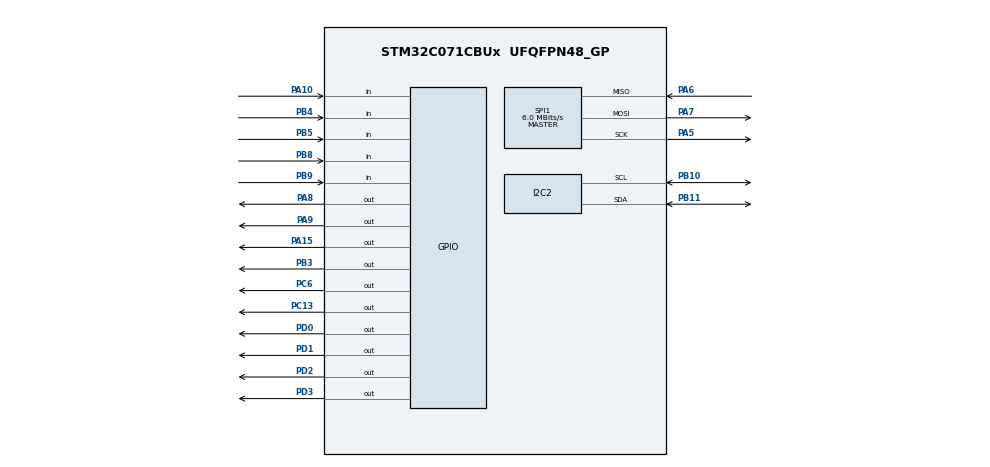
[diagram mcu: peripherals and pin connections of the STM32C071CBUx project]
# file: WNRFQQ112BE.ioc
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I2C2.OwnAddress=0x12
I2C2.Timing=0x10805D88
Mcu.Family=STM32C0
Mcu.Name=STM32C071CBUx
Mcu.Package=UFQFPN48_GP
NVIC.I2C2_IRQn=true\:0\:0\:false\:false\:true\:true\:true\:true
PA10.GPIO_PuPd=GPIO_PULLUP
PA10.Signal=GPIO_Input
PA15.Signal=GPIO_Output
PA4.Signal=SPI1_NSS
PA5.Mode=Full_Duplex_Master
PA5.Signal=SPI1_SCK
PA6.Mode=Full_Duplex_Master
PA6.Signal=SPI1_MISO
PA7.Mode=Full_Duplex_Master
PA7.Signal=SPI1_MOSI
PA8.Signal=GPIO_Output
PA9.Signal=GPIO_Output
PB10.GPIO_Pu=GPIO_PULLUP
PB10.Mode=I2C
PB10.Signal=I2C2_SCL
PB11.GPIO_Pu=GPIO_PULLUP
PB11.Mode=I2C
PB11.Signal=I2C2_SDA
PB3.Signal=GPIO_Output
PB4.Signal=GPIO_Input
PB5.Signal=GPIO_Input
PB8.Signal=GPIO_Input
PB9.Signal=GPIO_Input
PC13.Signal=GPIO_Output
PC6.Signal=GPIO_Output
PD0.Signal=GPIO_Output
PD1.Signal=GPIO_Output
PD2.Signal=GPIO_Output
PD3.Signal=GPIO_Output
PF0-OSC_IN(PF0).Mode=HSE-External-Oscillator
PF0-OSC_IN(PF0).Signal=RCC_OSC_IN
PF1-OSC_OUT(PF1).Mode=HSE-External-Oscillator
PF1-OSC_OUT(PF1).Signal=RCC_OSC_OUT
ProjectManager.HeapSize=0x200
ProjectManager.StackSize=0x400
ProjectManager.TargetToolchain=STM32CubeIDE
RCC.ADCFreq_Value=48000000
RCC.AHBFreq_Value=48000000
RCC.CortexFreq_Value=48000000
RCC.EXTERNAL_CLOCK_VALUE=12288000
RCC.HCLKFreq_Value=48000000
RCC.HSE_VALUE=8000000
RCC.HSI48_VALUE=48000000
RCC.HSISYSCLKDivider=RCC_HSI_DIV1
RCC.HSI_VALUE=48000000
RCC.LSE_VALUE=32768
RCC.SYSCLKFreq_VALUE=48000000
SPI1.BaudRatePrescaler=SPI_BAUDRATEPRESCALER_8
SPI1.CalculateBaudRate=6.0 MBits/s
SPI1.Direction=SPI_DIRECTION_2LINES
SPI1.Mode=SPI_MODE_MASTER
SPI1.VirtualType=VM_MASTER
board=custom

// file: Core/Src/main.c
/* USER CODE BEGIN Header */
/**
  ******************************************************************************
  * @file           : main.c
  * @brief          : Main program body
  ******************************************************************************
  * @attention
  *
  * Copyright (c) 2025 STMicroelectronics.
  * All rights reserved.
  *
  * This software is licensed under terms that can be found in the LICENSE file
  * in the root directory of this software component.
  * If no LICENSE file comes with this software, it is provided AS-IS.
  *
  ******************************************************************************
  */
/* USER CODE END Header */
#include "main.h"
#include "i2c.h"
#include "spi.h"
#include "gpio.h"
#include "i2c_slave.h"
#include "SSD1680.h"
#include <stdint.h>
#include "stm32c0xx_hal.h"
/* USER CODE BEGIN Includes */
HAL_StatusTypeDef HAL_Status;
/* USER CODE END Includes */

void SystemClock_Config(void);
extern const uint8_t checkerboard_buffer[4736];
/* USER CODE BEGIN PFP */
static void Fill_Checkerboard(void);
#define EPD_WIDTH 176
#define EPD_HEIGHT 264
uint8_t buffer[296 / 8 * 152]; // 計算出需要的緩衝區大小
/* USER CODE END PFP */

int main(void)
{

  /* MCU Configuration--------------------------------------------------------*/

  /* Reset of all peripherals, Initializes the Flash interface and the Systick. */
  HAL_Init();

  /* Configure the system clock */
  SystemClock_Config();

  /* Initialize all configured peripherals */
  MX_GPIO_Init();
  MX_I2C2_Init();
  MX_SPI1_Init();
  Epd_Init();
  Epd_Clear();
  HAL_Delay(1000);
  Epd_DisplayFrame(checkerboard_buffer);
  /* USER CODE BEGIN 2 */
  /* USER CODE BEGIN 2 */
  HAL_GPIO_WritePin(GPIOD, GPIO_PIN_3, GPIO_PIN_SET); // green
  HAL_GPIO_WritePin(GPIOD, GPIO_PIN_2, GPIO_PIN_SET);  // red
  HAL_GPIO_WritePin(GPIOB, GPIO_PIN_3, GPIO_PIN_SET); // blue
  HAL_Status = HAL_I2C_EnableListen_IT(&hi2c2) ;
  if (HAL_Status != HAL_OK)
  {
	  HAL_Delay(500); // 閃爍頻率 500ms
	  Error_Handler();
  }
  /* USER CODE END 2 */
  /* Infinite loop */
  while (1)
  {
	  if (HAL_Status != HAL_OK)
	  {
		  HAL_GPIO_WritePin(GPIOD, GPIO_PIN_3, GPIO_PIN_RESET);
		  HAL_Delay(500); // 閃爍頻率 500ms
	  }
	  else
		  HAL_GPIO_WritePin(GPIOB, GPIO_PIN_3, GPIO_PIN_RESET); // blue
    /* USER CODE BEGIN 3 */
  }
}

/*
  * @brief System Clock Configuration
  * @retval None
  */
void SystemClock_Config(void)
{
  RCC_OscInitTypeDef RCC_OscInitStruct = {0};
  RCC_ClkInitTypeDef RCC_ClkInitStruct = {0};

  __HAL_FLASH_SET_LATENCY(FLASH_LATENCY_1);

  /** Initializes the RCC Oscillators according to the specified parameters
  * in the RCC_OscInitTypeDef structure.
  */
  RCC_OscInitStruct.OscillatorType = RCC_OSCILLATORTYPE_HSI;
  RCC_OscInitStruct.HSIState = RCC_HSI_ON;
  RCC_OscInitStruct.HSIDiv = RCC_HSI_DIV1;
  RCC_OscInitStruct.HSICalibrationValue = RCC_HSICALIBRATION_DEFAULT;
  if (HAL_RCC_OscConfig(&RCC_OscInitStruct) != HAL_OK)
  {
    Error_Handler();
  }

  /** Initializes the CPU, AHB and APB buses clocks
  */
  RCC_ClkInitStruct.ClockType = RCC_CLOCKTYPE_HCLK|RCC_CLOCKTYPE_SYSCLK
                              |RCC_CLOCKTYPE_PCLK1;
  RCC_ClkInitStruct.SYSCLKSource = RCC_SYSCLKSOURCE_HSI;
  RCC_ClkInitStruct.SYSCLKDivider = RCC_SYSCLK_DIV1;
  RCC_ClkInitStruct.AHBCLKDivider = RCC_HCLK_DIV1;
  RCC_ClkInitStruct.APB1CLKDivider = RCC_APB1_DIV1;

  if (HAL_RCC_ClockConfig(&RCC_ClkInitStruct, FLASH_LATENCY_1) != HAL_OK)
  {
    Error_Handler();
  }
}

/* USER CODE END 4 */

void Error_Handler(void)
{
  __disable_irq();
  while (1)
  {
  }
}
